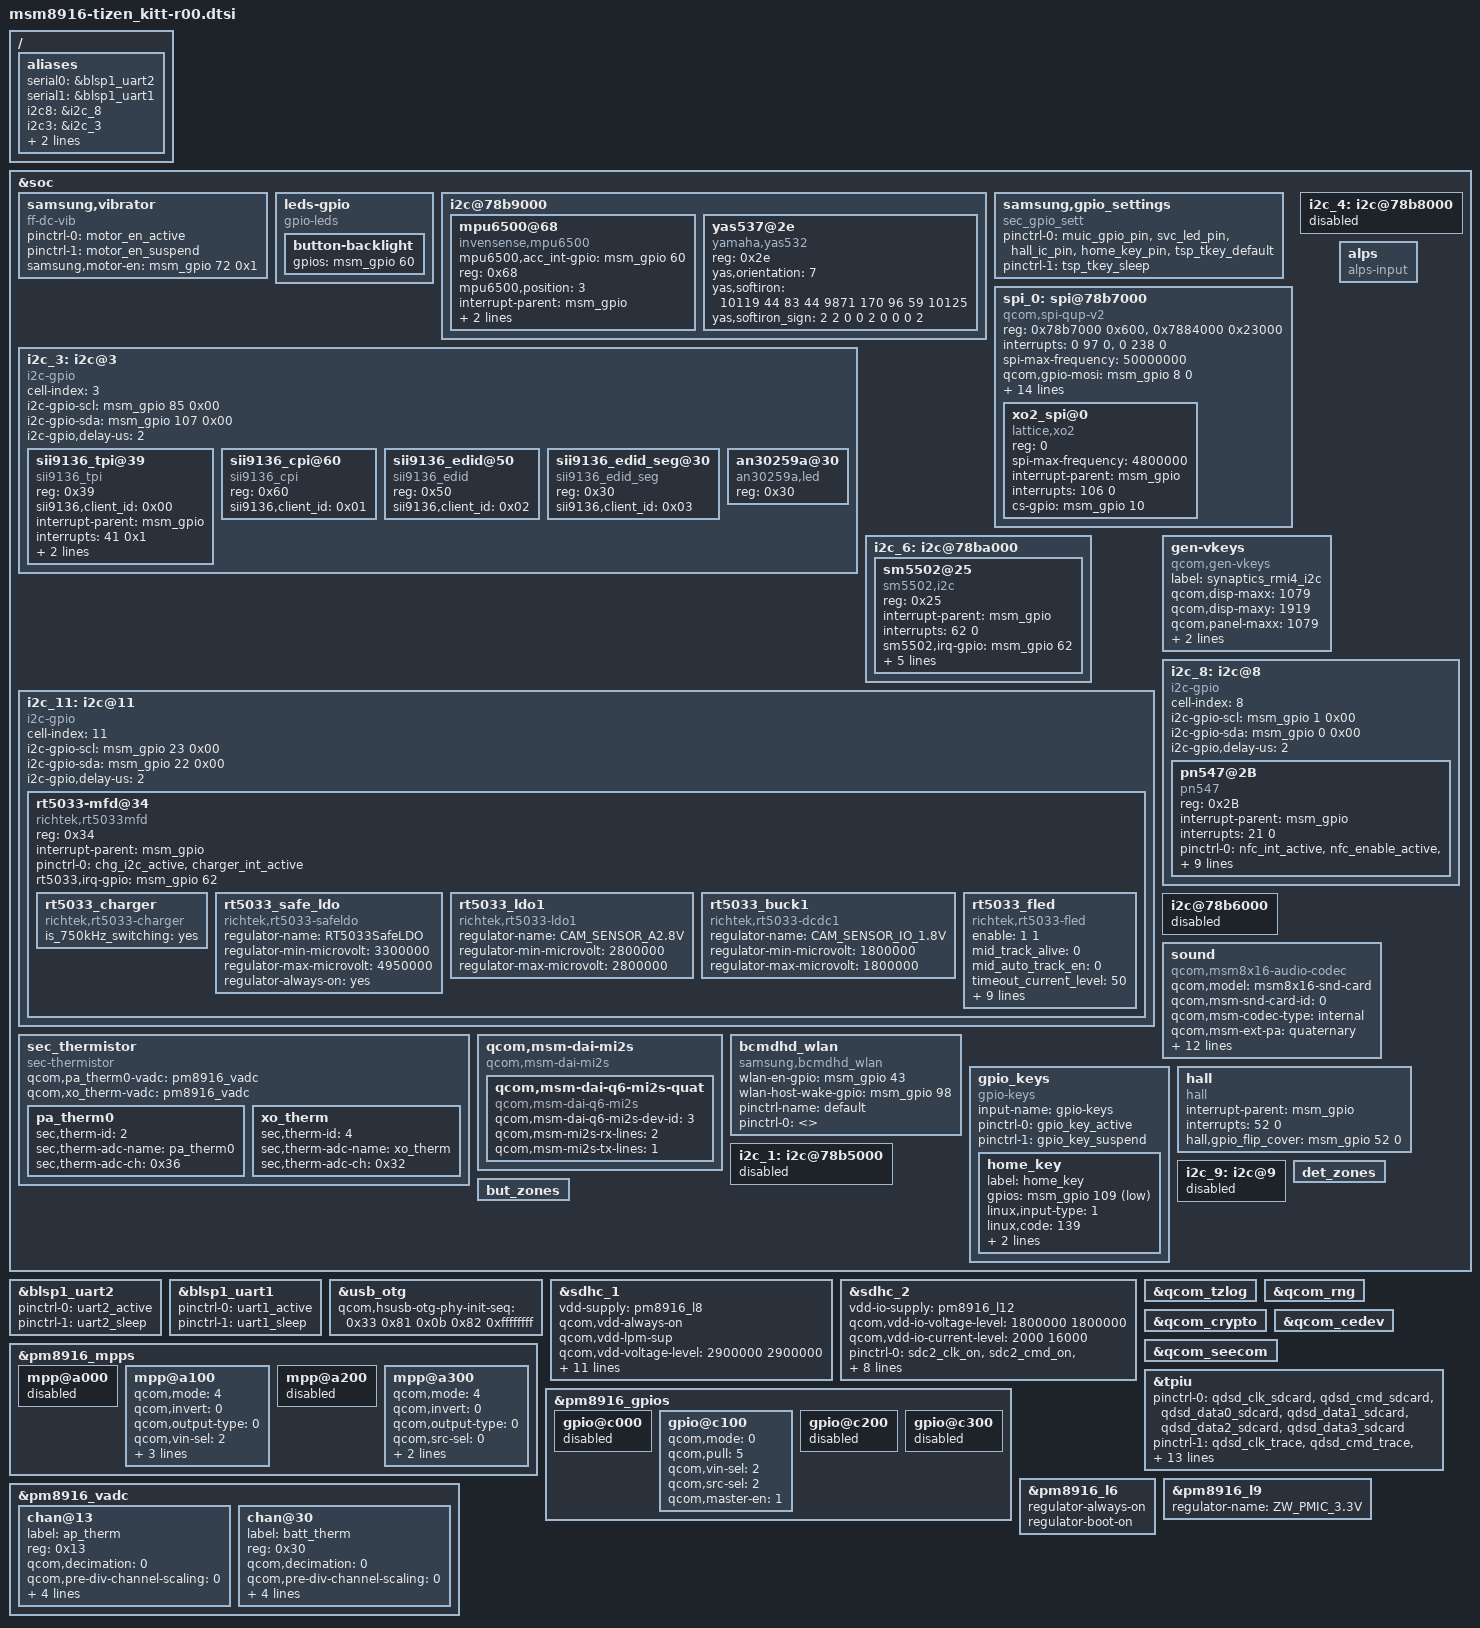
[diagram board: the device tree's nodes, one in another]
/*
 * Copyright (c) 2015, The Linux Foundation. All rights reserved.
 *
 * This program is free software; you can redistribute it and/or modify
 * it under the terms of the GNU General Public License version 2 and
 * only version 2 as published by the Free Software Foundation.
 *
 * This program is distributed in the hope that it will be useful,
 * but WITHOUT ANY WARRANTY; without even the implied warranty of
 * MERCHANTABILITY or FITNESS FOR A PARTICULAR PURPOSE.  See the
 * GNU General Public License for more details.
 */

#include "msm8916.dtsi"
#include "msm8916-pinctrl-tizen-kitt-r00.dtsi"
#include "msm8916-w1-r00.dtsi"
#include "msm8916-camera-kitt.dtsi"
#include "msm8916-camera-sensor-cdp-kitt.dtsi"

/ {
	aliases {
		serial0 = &blsp1_uart2;
		serial1 = &blsp1_uart1;

		/*i2c-gpio bus_id*/
		i2c8 = &i2c_8;
		i2c3 = &i2c_3;
		i2c11 = &i2c_11;

		/*spi-gpio bus_id*/
		spi2 = &spi_0;
	};
};

&soc {
	samsung,vibrator {
		pinctrl-names = "tlmm_motor_en_active","tlmm_motor_en_suspend";
		pinctrl-0 = <&motor_en_active>;
		pinctrl-1 = <&motor_en_suspend>;
		compatible = "ff-dc-vib";
		samsung,motor-en = <&msm_gpio 72 0x1>;
		status = "ok";
	};

	leds-gpio {
		compatible = "gpio-leds";
		button-backlight {
			gpios = <&msm_gpio 60 0>;
			status = "ok";
		};
	};

	i2c@78b9000 { /* BLSP1 QUP5 */
		status = "ok";

		mpu6500@68 {
			compatible = "invensense,mpu6500";
			mpu6500,acc_int-gpio = <&msm_gpio 60 0>;
			reg = <0x68>;
			mpu6500,position = <3>;
			interrupt-parent = <&msm_gpio>;
			interrupts = <60 0>;
			inven,orientation = <0 1 1 1 0 1 1 1 2>;
		};

		yas537@2e {
			compatible = "yamaha,yas532";
			reg = <0x2e>;
			yas,orientation = <7>;
			yas,softiron = <10119 44 83 44 9871 170 96 59 10125>;
			yas,softiron_sign = <2 2 0 0 2 0 0 0 2>;
		};
	};

	samsung,gpio_settings {
		compatible = "sec_gpio_sett";
		pinctrl-names = "sec_gpio_active","sec_gpio_suspend";
		pinctrl-0 = <&muic_gpio_pin &svc_led_pin &hall_ic_pin &home_key_pin &tsp_tkey_default>;
		pinctrl-1 = <&tsp_tkey_sleep>;
	};

	spi_0: spi@78b7000 { /* BLSP1 QUP3 */
		compatible = "qcom,spi-qup-v2";
		#address-cells = <1>;
		#size-cells = <0>;
		reg-names = "spi_physical", "spi_bam_physical";
		reg = <0x78b7000 0x600>, <0x7884000 0x23000>;
		interrupt-names = "spi_irq", "spi_bam_irq";
		interrupts = <0 97 0>, <0 238 0>;
		spi-max-frequency = <50000000>;

		qcom,gpio-mosi = <&msm_gpio 8 0>;
		qcom,gpio-miso = <&msm_gpio 9 0>;
		qcom,gpio-clk  = <&msm_gpio 11 0>;
		qcom,gpio-cs0  = <&msm_gpio 10 0>;

		pinctrl-names = "default", "sleep";
		pinctrl-0 = <&spi0_default &spi0_cs0_active>;
		pinctrl-1 = <&spi0_sleep &spi0_cs0_sleep>;
		clock-names = "iface_clk", "core_clk";
		clocks = <&clock_gcc clk_gcc_blsp1_ahb_clk>, <&clock_gcc clk_gcc_blsp1_qup3_spi_apps_clk>;
		qcom,infinite-mode = <0>;
		qcom,use-bam;
		qcom,use-pinctrl;
		qcom,ver-reg-exists;
		qcom,bam-consumer-pipe-index = <8>;
		qcom,bam-producer-pipe-index = <9>;
		qcom,master-id = <86>;
		status = "ok";

		xo2_spi@0 {
			compatible = "lattice,xo2";
			reg = <0>;

			spi-max-frequency = <4800000>;
			interrupt-parent = <&msm_gpio>;
			interrupts = <106 0>;
			cs-gpio = <&msm_gpio 10 0x00>;
			status = "ok";
		};
	};

	i2c_3: i2c@3 {
		cell-index = <3>;
		compatible = "i2c-gpio";
		i2c-gpio-scl = <&msm_gpio 85 0x00>;
		i2c-gpio-sda = <&msm_gpio 107 0x00>;
		i2c-gpio,delay-us = <2>;
		#address-cells = <1>;
		#size-cells = <0>;

		sii9136_tpi@39 {
			compatible = "sii9136_tpi";
			reg = <0x39>; /* 0x72 >> 1 */
			sii9136,client_id = <0x00>;

			interrupt-parent = <&msm_gpio>;
			interrupts = <41 0x1>;

			sii9136,gpio_mhl_reset = <&msm_gpio 40 0x00>;
			sii9136,gpio_mhl_irq = <&msm_gpio 41 0x00>;
		};

		sii9136_cpi@60 {
			compatible = "sii9136_cpi";
			reg = <0x60>;  /* 0xC0 >> 1 */
			sii9136,client_id = <0x01>;
		};

		sii9136_edid@50 {
			compatible = "sii9136_edid";
			reg = <0x50>;   /* 0xA0 >> 1 */
			sii9136,client_id = <0x02>;
		};

		sii9136_edid_seg@30 {
			compatible = "sii9136_edid_seg";
			reg = <0x30>;  /* 0x60 >> 1 */
			sii9136,client_id = <0x03>;
		};

		an30259a@30 {
			compatible = "an30259a,led";
			reg = <0x30>;
		};
	};

	i2c_4: i2c@78b8000 { /* BLSP1 QUP4 */
		status="disable";
	};

	i2c_6: i2c@78ba000 { /* BLSP1 QUP6 */
		status = "ok";

		sm5502@25{
			compatible = "sm5502,i2c";
			reg = <0x25>;
			interrupt-parent = <&msm_gpio>;
			interrupts= <62 0>;
			sm5502,irq-gpio = <&msm_gpio 62 0x00>;
			sm5502,gpio-sda = <&msm_gpio 22 0x00>;
			sm5502,gpio-scl = <&msm_gpio 23 0x00>;
			sm5502,uarton-gpio = <&msm_gpio 114 0x00>;
			pinctrl-names = "sm5502_i2c_active","sm5502_i2c_suspend";
			pinctrl-0 = <&muic_i2c_active &muic_int_pin>;
			pinctrl-1 = <&muic_i2c_suspend &muic_int_pin>;
		};
	};

	i2c_11:i2c@11 {
		cell-index = <11>;
		compatible = "i2c-gpio";
		i2c-gpio-scl = <&msm_gpio 23 0x00>;
		i2c-gpio-sda = <&msm_gpio 22 0x00>;
		i2c-gpio,delay-us = <2>;
		#address-cells = <1>;
		#size-cells = <0>;

		rt5033-mfd@34 {
			compatible = "richtek,rt5033mfd";
			reg = <0x34>;
			interrupt-parent = <&msm_gpio>;
			pinctrl-names = "default";
			pinctrl-0 = <&chg_i2c_active &charger_int_active>;
			rt5033,irq-gpio = <&msm_gpio 62 0x00>;

			rt5033_charger {
				compatible = "richtek,rt5033-charger";
				is_750kHz_switching = "yes";
			};

			rt5033_safe_ldo {
				compatible = "richtek,rt5033-safeldo";
				regulator-name = "RT5033SafeLDO"; /* constraints->name, change name by yourself*/
				regulator-min-microvolt = <3300000>;
				regulator-max-microvolt = <4950000>; /* if max == min then apply_uV = 1 */
				regulator-always-on = "yes";
			};

			rt5033_ldo1 {
				compatible = "richtek,rt5033-ldo1";
				regulator-name = "CAM_SENSOR_A2.8V"; /* change name by yourself */
				regulator-min-microvolt = <2800000>;
				regulator-max-microvolt = <2800000>; /* max == min then apply_uV = 1 */
			};

			rt5033_buck1 {
				compatible = "richtek,rt5033-dcdc1";
				regulator-name = "CAM_SENSOR_IO_1.8V"; /* change name by yourself */
				regulator-min-microvolt = <1800000>;
				regulator-max-microvolt = <1800000>; /* max == min then apply_uV = 1 */
			};

			rt5033_fled {
				compatible = "richtek,rt5033-fled";
				enable = <1 1>;
				mid_track_alive = <0>;
				mid_auto_track_en = <0>;
				timeout_current_level = <50>;
				strobe_current = <500>;
				strobe_timeout = <544>;
				torch_current = <63>;
				lv_protection = <3000>;
				mid_level = <4400>;
				rt5033,led1-gpio = <&msm_gpio 34 0x00>;
				rt5033,led2-gpio = <&msm_gpio 36 0x00>;
				pinctrl-names = "fled_defualt","fled_sleep";
				pinctrl-0 = <&gpio_led_default>;
				pinctrl-1 = <&gpio_led_sleep>;
			};
		};
	};

	gen-vkeys {
		compatible = "qcom,gen-vkeys";
		label = "synaptics_rmi4_i2c";
		qcom,disp-maxx = <1079>;
		qcom,disp-maxy = <1919>;
		qcom,panel-maxx = <1079>;
		qcom,panel-maxy = <2084>;
		qcom,key-codes = <158 139 172 217>;
	};

	sec_thermistor {
		compatible = "sec-thermistor";
		qcom,pa_therm0-vadc = <&pm8916_vadc>;
		qcom,xo_therm-vadc = <&pm8916_vadc>;

		pa_therm0 {
			sec,therm-id = <2>; /* SEC_THERM_PAM0 */
			sec,therm-adc-name = "pa_therm0";
			sec,therm-adc-ch = <0x36>;
		};

		xo_therm {
			sec,therm-id = <4>; /* SEC_THERM_XO */
			sec,therm-adc-name = "xo_therm";
			sec,therm-adc-ch = <0x32>;
		};
	};

	alps {
		compatible = "alps-input";
	};

	i2c_8: i2c@8 {
		cell-index = <8>;
		compatible = "i2c-gpio";
		i2c-gpio-scl = <&msm_gpio 1 0x00>;
		i2c-gpio-sda = <&msm_gpio 0 0x00>;
		#address-cells = <1>;
		#size-cells = <0>;
		i2c-gpio,delay-us = <2>;

		pn547@2B {
			compatible = "pn547";
			reg = <0x2B>;
			interrupt-parent = <&msm_gpio>;
			interrupts = <21 0>;
			pinctrl-names = "nfc_active","nfc_suspend";
			pinctrl-0 = <&nfc_int_active &nfc_enable_active &nfc_firmware_active &nfc_i2c_active>;
			pinctrl-1 = <&nfc_int_suspend &nfc_enable_suspend &nfc_firmware_suspend &nfc_i2c_suspend>;
			pn547,firm-gpio = <&msm_gpio 49 0x00>;
			pn547,ven-gpio = <&msm_gpio 20 0x00>;
			pn547,irq-gpio = <&msm_gpio 21 0x01>;
			nfc_ldo-supply = <&pm8916_l14>;
			clocks = <&clock_rpm clk_bb_clk2_pin>;
			clock-names = "nfc_clock";
		};
	};

	i2c@78b6000 { /* BLSP1 QUP2 */
		status = "disable";
	};

	/* Over-riding model specific changes */
	sound {
		compatible = "qcom,msm8x16-audio-codec";
		qcom,model = "msm8x16-snd-card"; /*qcom,model = "msm8x16-snd-card-mtp";*/
		qcom,msm-snd-card-id = <0>;
		qcom,msm-codec-type = "internal";
		qcom,msm-ext-pa = "quaternary";
		qcom,audio-routing =
			"RX_BIAS", "MCLK",
			"SPK_RX_BIAS", "MCLK",
			"INT_LDO_H", "MCLK",
			"MIC BIAS External", "Handset Mic",
			"MIC BIAS External2", "Secondary Mic",
			"AMIC1", "MIC BIAS External",
			"AMIC2", "Headset Mic",
			"AMIC3", "MIC BIAS External2";
		pinctrl-names =
			"cdc_lines_act",
			"cdc_lines_sus",
			"cdc_lines_quat_ext_act",
			"cdc_lines_quat_ext_sus";
		pinctrl-0 = <&cdc_pdm_lines_act>;
		pinctrl-1 = <&cdc_pdm_lines_sus>;
		pinctrl-2 = <&cdc_pdm_lines_act &ext_cdc_tlmm_lines_act>;
		pinctrl-3 = <&cdc_pdm_lines_sus &ext_cdc_tlmm_lines_sus>;
	};

	qcom,msm-dai-mi2s {
		compatible = "qcom,msm-dai-mi2s";

		qcom,msm-dai-q6-mi2s-quat {
			compatible = "qcom,msm-dai-q6-mi2s";
			qcom,msm-dai-q6-mi2s-dev-id = <3>;
			/* SWAP D-IN, D-OUT */
			qcom,msm-mi2s-rx-lines = <2>;
			qcom,msm-mi2s-tx-lines = <1>;
		};
	};

	bcmdhd_wlan {
		compatible = "samsung,bcmdhd_wlan";
		wlan-en-gpio = <&msm_gpio 43 0>;
		wlan-host-wake-gpio = <&msm_gpio 98 0>;
		pinctrl-name = "default";
		pinctrl-0 = <>;
	};
};

&blsp1_uart2 {
	status = "ok";
	pinctrl-names = "default","sleep";
	pinctrl-0 = <&uart2_active>;
	pinctrl-1 = <&uart2_sleep>;
};

&blsp1_uart1 {
	status = "ok";
	pinctrl-names = "default","sleep";
	pinctrl-0 = <&uart1_active>;
	pinctrl-1 = <&uart1_sleep>;
};

&soc {
	gpio_keys {
		compatible = "gpio-keys";
		input-name = "gpio-keys";
		pinctrl-names = "tlmm_gpio_key_active","tlmm_gpio_key_suspend";
		pinctrl-0 = <&gpio_key_active>;
		pinctrl-1 = <&gpio_key_suspend>;

		home_key {
			label = "home_key";
			gpios = <&msm_gpio 109 0x1>;
			linux,input-type = <1>;
			linux,code = <139>;
			gpio-key,wakeup;
			debounce-interval = <15>;
		};

		/*
		volume_up {
			label = "volume_up";
			gpios = <&msm_gpio 107 0x1>;
			linux,input-type = <1>;
			linux,code = <115>;
			debounce-interval = <15>;
		};
		*/
	};

	hall {
		status = "okay";
		compatible = "hall";
		interrupt-parent = <&msm_gpio>;
		interrupts = <52 0>;
		hall,gpio_flip_cover = <&msm_gpio 52 0>;

	};

	i2c_1: i2c@78b5000 { /* BLSP1 QUP1 */
		status="disable";
	};

	i2c_9:i2c@9 { /*SM5502 GPIO-I2C*/
		status="disable";
	};

	det_zones: det_zones {
		#list-det-cells = <4>;
	};

	but_zones: but_zones {
		#list-but-cells = <3>;
	};
};

&usb_otg {
	qcom,hsusb-otg-phy-init-seq = <0x33 0x81 0x0b 0x82 0xffffffff>;
};

&sdhc_1 {
	vdd-supply = <&pm8916_l8>;
	qcom,vdd-always-on;
	qcom,vdd-lpm-sup;
	qcom,vdd-voltage-level = <2900000 2900000>;
	qcom,vdd-current-level = <200 400000>;

	vdd-io-supply = <&pm8916_l5>;
	qcom,vdd-io-always-on;
	qcom,vdd-io-lpm-sup;
	qcom,vdd-io-voltage-level = <1800000 1800000>;
	qcom,vdd-io-current-level = <200 60000>;

	pinctrl-names = "active", "sleep";
	pinctrl-0 = <&sdc1_clk_on &sdc1_cmd_on &sdc1_data_on>;
	pinctrl-1 = <&sdc1_clk_off &sdc1_cmd_off &sdc1_data_off>;

	qcom,nonremovable;

	status = "ok";
};

&sdhc_2 {
	vdd-io-supply = <&pm8916_l12>;
	qcom,vdd-io-voltage-level = <1800000 1800000>;
	qcom,vdd-io-current-level = <2000 16000>;

	pinctrl-names = "active", "sleep";
	pinctrl-0 = <&sdc2_clk_on &sdc2_cmd_on &sdc2_data_on>;
	pinctrl-1 = <&sdc2_clk_off &sdc2_cmd_off &sdc2_data_off>;

	#address-cells = <0>;
	interrupt-parent = <&sdhc_2>;
	interrupts = <0 1>;
	#interrupt-cells = <1>;
	interrupt-map-mask = <0xffffffff>;
	interrupt-map = <0 &intc 0 125 0
			1 &intc 0 221 0>;
	interrupt-names = "hc_irq", "pwr_irq";

	status-cb = <2>;
	status = "ok";
};

&pm8916_mpps {
	mpp@a000 { /* MPP 1 */
		/* VDD_PX */
		status = "disabled";
	};

	mpp@a100 { /* MPP 2 */
		status = "ok";
		qcom,mode = <4>; // AIN input
		qcom,invert = <0>; //No Invert
		qcom,output-type = <0>; //CMOS
		qcom,vin-sel = <2>; //PM8971_S3 1.8v
		qcom,src-sel = <0>; //MPP Constant
		qcom,ain-route = <1>; // QPNP_PIN_AIN_AMUX_CH6 = 1 for MPP2
		qcom,master-en = <1>; // Function constant
	};

	mpp@a200 { /* MPP 3 */
		/* VREF DAC */
		status = "disabled";
	};

	mpp@a300 { /* MPP 4 */
		status = "ok";
		qcom,mode = <4>; // AIN input
		qcom,invert = <0>; //No Invert
		qcom,output-type = <0>; //CMOS
		qcom,src-sel = <0>; //MPP Constant
		qcom,ain-route = <3>; // QPNP_PIN_AIN_AMUX_CH8 = 3 for MPP4
		qcom,master-en = <1>; // Function constant
	};
};

&pm8916_gpios {
	gpio@c000 { /* GPIO 1 */
		/* Battery UICC Alarm */
		status = "disabled";
	};

	gpio@c100 { /* GPIO 2 */
		/* NFC_CLK_REQ */
		qcom,mode = <0>; /* QPNP_PIN_MODE_DIG_IN */
		qcom,pull = <5>; /* QPNP_PIN_PULL_NO */
		qcom,vin-sel = <2>; /* QPNP_PIN_VIN2 */
		qcom,src-sel = <2>; /* QPNP_PIN_SEL_FUNC_1 */
		qcom,master-en = <1>;
	};

	gpio@c200 { /* GPIO 3 */
		/* External regulator control for WTR */
		status = "disabled";
	};

	gpio@c300 { /* GPIO 4 */
		/* External regulator control for APC */
		status = "disabled";
	};
};

&qcom_tzlog {
	status = "okay";
};

&qcom_rng {
	status = "okay";
};

&qcom_crypto {
	status = "okay";
};

&qcom_cedev {
	status = "okay";
};

&qcom_seecom {
	status = "okay";
};

/* CoreSight */
&tpiu {
	pinctrl-names = "sdcard", "trace", "swduart",
			"swdtrc", "jtag", "spmi";
	/* NIDnT */
	pinctrl-0 = <&qdsd_clk_sdcard &qdsd_cmd_sdcard
			&qdsd_data0_sdcard &qdsd_data1_sdcard
			&qdsd_data2_sdcard &qdsd_data3_sdcard>;
	pinctrl-1 = <&qdsd_clk_trace &qdsd_cmd_trace
			&qdsd_data0_trace &qdsd_data1_trace
			&qdsd_data2_trace &qdsd_data3_trace>;
	pinctrl-2 = <&qdsd_cmd_swduart &qdsd_data0_swduart
			&qdsd_data1_swduart &qdsd_data2_swduart
			&qdsd_data3_swduart>;
	pinctrl-3 = <&qdsd_clk_swdtrc &qdsd_cmd_swdtrc
			&qdsd_data0_swdtrc &qdsd_data1_swdtrc
			&qdsd_data2_swdtrc &qdsd_data3_swdtrc>;
	pinctrl-4 = <&qdsd_cmd_jtag &qdsd_data0_jtag
			&qdsd_data1_jtag &qdsd_data2_jtag
			&qdsd_data3_jtag>;
	pinctrl-5 = <&qdsd_clk_spmi &qdsd_cmd_spmi
			&qdsd_data0_spmi &qdsd_data3_spmi>;
};

&pm8916_l6 {
	regulator-always-on;
	regulator-boot-on;
};

&pm8916_l9 {
	regulator-name = "ZW_PMIC_3.3V";
};

&pm8916_vadc {
	chan@13 {
		label = "ap_therm";
		reg = <0x13>; // channel 19 for MPP4 , 1:1scale
		qcom,decimation = <0>;
		qcom,pre-div-channel-scaling = <0>; // 1:1scale
		qcom,calibration-type = "ratiometric";
		qcom,scale-function = <1>;
		qcom,hw-settle-time = <2>;
		qcom,fast-avg-setup = <0>;
	};

	chan@30 {
		label = "batt_therm";
		reg = <0x30>; // LR_MUX1_BATT_THERM , 1:1scale
		qcom,decimation = <0>;
		qcom,pre-div-channel-scaling = <0>; // 1:1scale
		qcom,calibration-type = "ratiometric";
		qcom,scale-function = <1>;
		qcom,hw-settle-time = <2>;
		qcom,fast-avg-setup = <0>;
	};
};
